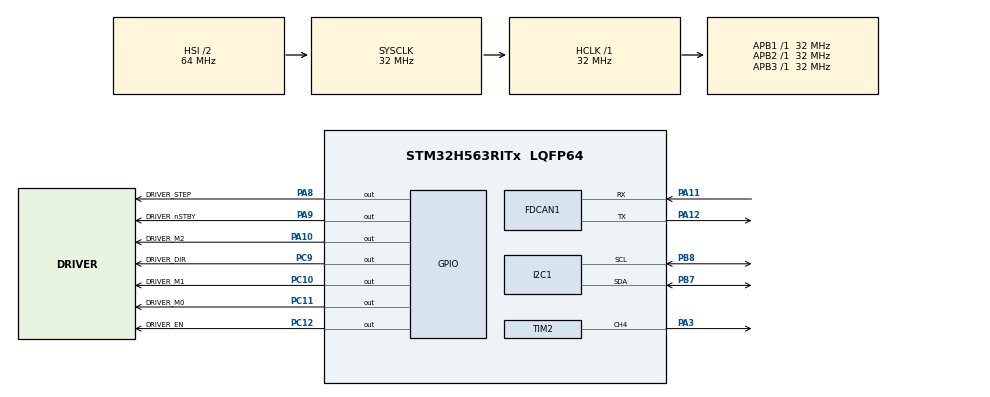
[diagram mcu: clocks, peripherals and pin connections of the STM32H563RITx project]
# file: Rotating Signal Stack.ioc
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BOOTPATH.BootPathName=LEGACY
BOOTPATH.UserSelectedBootPath=LEGACY
CORTEX_M33_NS.Number-Cortex_Memory_Protection_Unit_Region0_OTP_RO_AREAS_Settings=MPU_REGION_NUMBER0
CORTEX_M33_NS.default_mode_Activation=1
CORTEX_M33_NS.userName=CORTEX_M33
FDCAN1.CalculateBaudRateNominal=520833
FDCAN1.CalculateTimeBitNominal=1920
FDCAN1.CalculateTimeQuantumNominal=640.0
I2C1.Timing=0x00707CBB
Mcu.Family=STM32H5
Mcu.Name=STM32H563RITx
Mcu.Package=LQFP64
NVIC.PriorityGroup=NVIC_PRIORITYGROUP_4
NVIC.TIM2_IRQn=true\:0\:0\:false\:false\:true\:true\:true\:true
PA10.GPIO_Label=DRIVER_M2
PA10.Signal=GPIO_Output
PA11.Mode=FDCAN_Activate
PA11.Signal=FDCAN1_RX
PA12.Mode=FDCAN_Activate
PA12.Signal=FDCAN1_TX
PA13(JTMS/SWDIO).Mode=JTAG_4_pins
PA13(JTMS/SWDIO).Signal=DEBUG_JTMS-SWDIO
PA14(JTCK/SWCLK).Mode=JTAG_4_pins
PA14(JTCK/SWCLK).Signal=DEBUG_JTCK-SWCLK
PA15(JTDI).Mode=JTAG_4_pins
PA15(JTDI).Signal=DEBUG_JTDI
PA3.Signal=S_TIM2_CH4
PA8.GPIO_Label=DRIVER_STEP
PA8.Signal=GPIO_Output
PA9.GPIO_Label=DRIVER_nSTBY
PA9.Signal=GPIO_Output
PB3(JTDO/TRACESWO).Mode=JTAG_4_pins
PB3(JTDO/TRACESWO).Signal=DEBUG_JTDO-SWO
PB7.Mode=I2C
PB7.Signal=I2C1_SDA
PB8.Mode=I2C
PB8.Signal=I2C1_SCL
PC10.GPIO_Label=DRIVER_M1
PC10.Signal=GPIO_Output
PC11.GPIO_Label=DRIVER_M0
PC11.Signal=GPIO_Output
PC12.GPIO_Label=DRIVER_EN
PC12.Signal=GPIO_Output
PC9.GPIO_Label=DRIVER_DIR
PC9.Signal=GPIO_Output
ProjectManager.HeapSize=0x200
ProjectManager.StackSize=0x400
ProjectManager.TargetToolchain=STM32CubeIDE
RCC.ADCFreq_Value=32000000
RCC.AHBFreq_Value=32000000
RCC.APB1Freq_Value=32000000
RCC.APB1TimFreq_Value=32000000
RCC.APB2Freq_Value=32000000
RCC.APB2TimFreq_Value=32000000
RCC.APB3Freq_Value=32000000
RCC.CSI_VALUE=4000000
RCC.CortexFreq_Value=32000000
RCC.EPOD_VALUE=4000000
RCC.HCLKFreq_Value=32000000
RCC.HSE_VALUE=25000000
RCC.HSI48_VALUE=48000000
RCC.HSI_VALUE=64000000
RCC.LSE_VALUE=32768
RCC.LSIRC_VALUE=32000
RCC.SYSCLKFreq_VALUE=32000000
RCC.USBFreq_Value=48000000
RCC.VCOOutputFreq_Value=516000000
SH.S_TIM2_CH4.0=TIM2_CH4,PWM Generation4 CH4
TIM2.Channel-PWM\ Generation4\ CH4=TIM_CHANNEL_4
TIM2.PeriodNoDither=(32000000/20000) 
TIM2.Prescaler=20000
VP_BOOTPATH_VS_BOOTPATH.Mode=BP_Activate
VP_CORTEX_M33_NS_VS_Hclk.Mode=Hclk_Mode
VP_ICACHE_VS_ICACHE.Mode=DirectMappedCache
VP_MEMORYMAP_VS_MEMORYMAP.Mode=CurAppReg
VP_PWR_VS_LPOM.Mode=PowerOptimisation
VP_PWR_VS_SECSignals.Mode=Security/Privilege
VP_TIM2_VS_ClockSourceINT.Mode=Internal
board=custom

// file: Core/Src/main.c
/* USER CODE BEGIN Header */
/**
  ******************************************************************************
  * @file           : main.c
  * @brief          : Main program body
  ******************************************************************************
  * @attention
  *
  * Copyright (c) 2026 STMicroelectronics.
  * All rights reserved.
  *
  * This software is licensed under terms that can be found in the LICENSE file
  * in the root directory of this software component.
  * If no LICENSE file comes with this software, it is provided AS-IS.
  *
  ******************************************************************************
  */
/* USER CODE END Header */
#include "main.h"

/* USER CODE BEGIN PD */
#define TIM_DAY 1
/* USER CODE END PD */

FDCAN_HandleTypeDef hfdcan1;

I2C_HandleTypeDef hi2c1;

TIM_HandleTypeDef htim2;

void SystemClock_Config(void);
static void MPU_Config(void);
static void MX_GPIO_Init(void);
static void MX_ICACHE_Init(void);
static void MX_FDCAN1_Init(void);
static void MX_I2C1_Init(void);
static void MX_TIM2_Init(void);
/* USER CODE BEGIN PFP */
void HAL_TIM_PeriodElapsedCallback(TIM_HandleTypeDef *htim) {
    if (htim->Instance == TIM4) {
    	HAL_GPIO_TogglePin(HEARTBEAT_GPIO_Port, HEARTBEAT_Pin);
    }
}
/* USER CODE END PFP */

int main(void)
{

  /* MCU Configuration--------------------------------------------------------*/

  /* MPU Configuration--------------------------------------------------------*/
  MPU_Config();

  /* Reset of all peripherals, Initializes the Flash interface and the Systick. */
  HAL_Init();

  /* Configure the system clock */
  SystemClock_Config();

  /* Initialize all configured peripherals */
  MX_GPIO_Init();
  MX_ICACHE_Init();
  MX_FDCAN1_Init();
  MX_I2C1_Init();
  MX_TIM2_Init();
  /* USER CODE BEGIN 2 */
  HAL_TIM_Base_Start_IT(&htim2);
  __HAL_RCC_TIM2_CLK_ENABLE();
  HAL_GPIO_WritePin(DRIVER_M0_GPIO_Port, DRIVER_M0_Pin, GPIO_PIN_RESET);
  HAL_GPIO_WritePin(DRIVER_M1_GPIO_Port, DRIVER_M1_Pin, GPIO_PIN_RESET);
  HAL_GPIO_WritePin(DRIVER_M2_GPIO_Port, DRIVER_M2_Pin, GPIO_PIN_RESET);
  HAL_GPIO_WritePin(DRIVER_EN_GPIO_Port, DRIVER_EN_Pin, GPIO_PIN_RESET);
  HAL_GPIO_WritePin(DRIVER_DIRECTION_GPIO_Port, DRIVER_DIRECTION_Pin, GPIO_PIN_SET);
  HAL_GPIO_WritePin(DRIVER_STEP_CLOCK_GPIO_Port, DRIVER_STEP_CLOCK_Pin, GPIO_PIN_RESET);
  HAL_GPIO_WritePin(DRIVER_nSTBY_GPIO_Port, DRIVER_nSTBY_Pin, GPIO_PIN_SET);
  /* USER CODE END 2 */

  /* Infinite loop */
  /* USER CODE BEGIN WHILE */
  while (TIM_DAY)
  {
    /* USER CODE END WHILE */

  }
}

void SystemClock_Config(void)
{
  RCC_OscInitTypeDef RCC_OscInitStruct = {0};
  RCC_ClkInitTypeDef RCC_ClkInitStruct = {0};

  /** Configure the main internal regulator output voltage
  */
  __HAL_PWR_VOLTAGESCALING_CONFIG(PWR_REGULATOR_VOLTAGE_SCALE3);

  while(!__HAL_PWR_GET_FLAG(PWR_FLAG_VOSRDY)) {}

  /** Initializes the RCC Oscillators according to the specified parameters
  * in the RCC_OscInitTypeDef structure.
  */
  RCC_OscInitStruct.OscillatorType = RCC_OSCILLATORTYPE_HSI|RCC_OSCILLATORTYPE_HSE;
  RCC_OscInitStruct.HSEState = RCC_HSE_OFF;
  RCC_OscInitStruct.HSIState = RCC_HSI_ON;
  RCC_OscInitStruct.HSIDiv = RCC_HSI_DIV2;
  RCC_OscInitStruct.HSICalibrationValue = RCC_HSICALIBRATION_DEFAULT;
  RCC_OscInitStruct.PLL.PLLState = RCC_PLL_NONE;
  if (HAL_RCC_OscConfig(&RCC_OscInitStruct) != HAL_OK)
  {
    Error_Handler();
  }

  /** Initializes the CPU, AHB and APB buses clocks
  */
  RCC_ClkInitStruct.ClockType = RCC_CLOCKTYPE_HCLK|RCC_CLOCKTYPE_SYSCLK
                              |RCC_CLOCKTYPE_PCLK1|RCC_CLOCKTYPE_PCLK2
                              |RCC_CLOCKTYPE_PCLK3;
  RCC_ClkInitStruct.SYSCLKSource = RCC_SYSCLKSOURCE_HSI;
  RCC_ClkInitStruct.AHBCLKDivider = RCC_SYSCLK_DIV1;
  RCC_ClkInitStruct.APB1CLKDivider = RCC_HCLK_DIV1;
  RCC_ClkInitStruct.APB2CLKDivider = RCC_HCLK_DIV1;
  RCC_ClkInitStruct.APB3CLKDivider = RCC_HCLK_DIV1;

  if (HAL_RCC_ClockConfig(&RCC_ClkInitStruct, FLASH_LATENCY_1) != HAL_OK)
  {
    Error_Handler();
  }

  /** Configure the programming delay
  */
  __HAL_FLASH_SET_PROGRAM_DELAY(FLASH_PROGRAMMING_DELAY_0);
}

static void MX_FDCAN1_Init(void)
{

  hfdcan1.Instance = FDCAN1;
  hfdcan1.Init.ClockDivider = FDCAN_CLOCK_DIV1;
  hfdcan1.Init.FrameFormat = FDCAN_FRAME_CLASSIC;
  hfdcan1.Init.Mode = FDCAN_MODE_NORMAL;
  hfdcan1.Init.AutoRetransmission = DISABLE;
  hfdcan1.Init.TransmitPause = DISABLE;
  hfdcan1.Init.ProtocolException = DISABLE;
  hfdcan1.Init.NominalPrescaler = 16;
  hfdcan1.Init.NominalSyncJumpWidth = 1;
  hfdcan1.Init.NominalTimeSeg1 = 1;
  hfdcan1.Init.NominalTimeSeg2 = 1;
  hfdcan1.Init.DataPrescaler = 1;
  hfdcan1.Init.DataSyncJumpWidth = 1;
  hfdcan1.Init.DataTimeSeg1 = 1;
  hfdcan1.Init.DataTimeSeg2 = 1;
  hfdcan1.Init.StdFiltersNbr = 0;
  hfdcan1.Init.ExtFiltersNbr = 0;
  hfdcan1.Init.TxFifoQueueMode = FDCAN_TX_FIFO_OPERATION;
  if (HAL_FDCAN_Init(&hfdcan1) != HAL_OK)
  {
    Error_Handler();
  }

}

static void MX_I2C1_Init(void)
{

  hi2c1.Instance = I2C1;
  hi2c1.Init.Timing = 0x00707CBB;
  hi2c1.Init.OwnAddress1 = 0;
  hi2c1.Init.AddressingMode = I2C_ADDRESSINGMODE_7BIT;
  hi2c1.Init.DualAddressMode = I2C_DUALADDRESS_DISABLE;
  hi2c1.Init.OwnAddress2 = 0;
  hi2c1.Init.OwnAddress2Masks = I2C_OA2_NOMASK;
  hi2c1.Init.GeneralCallMode = I2C_GENERALCALL_DISABLE;
  hi2c1.Init.NoStretchMode = I2C_NOSTRETCH_DISABLE;
  if (HAL_I2C_Init(&hi2c1) != HAL_OK)
  {
    Error_Handler();
  }

  /** Configure Analogue filter
  */
  if (HAL_I2CEx_ConfigAnalogFilter(&hi2c1, I2C_ANALOGFILTER_ENABLE) != HAL_OK)
  {
    Error_Handler();
  }

  /** Configure Digital filter
  */
  if (HAL_I2CEx_ConfigDigitalFilter(&hi2c1, 0) != HAL_OK)
  {
    Error_Handler();
  }

}

static void MX_ICACHE_Init(void)
{

  /** Enable instruction cache in 1-way (direct mapped cache)
  */
  if (HAL_ICACHE_ConfigAssociativityMode(ICACHE_1WAY) != HAL_OK)
  {
    Error_Handler();
  }
  if (HAL_ICACHE_Enable() != HAL_OK)
  {
    Error_Handler();
  }

}

static void MX_TIM2_Init(void)
{

  TIM_ClockConfigTypeDef sClockSourceConfig = {0};
  TIM_MasterConfigTypeDef sMasterConfig = {0};
  TIM_OC_InitTypeDef sConfigOC = {0};

  htim2.Instance = TIM2;
  htim2.Init.Prescaler = 20000;
  htim2.Init.CounterMode = TIM_COUNTERMODE_UP;
  htim2.Init.Period = 1600;
  htim2.Init.ClockDivision = TIM_CLOCKDIVISION_DIV1;
  htim2.Init.AutoReloadPreload = TIM_AUTORELOAD_PRELOAD_DISABLE;
  if (HAL_TIM_Base_Init(&htim2) != HAL_OK)
  {
    Error_Handler();
  }
  sClockSourceConfig.ClockSource = TIM_CLOCKSOURCE_INTERNAL;
  if (HAL_TIM_ConfigClockSource(&htim2, &sClockSourceConfig) != HAL_OK)
  {
    Error_Handler();
  }
  if (HAL_TIM_PWM_Init(&htim2) != HAL_OK)
  {
    Error_Handler();
  }
  sMasterConfig.MasterOutputTrigger = TIM_TRGO_RESET;
  sMasterConfig.MasterSlaveMode = TIM_MASTERSLAVEMODE_DISABLE;
  if (HAL_TIMEx_MasterConfigSynchronization(&htim2, &sMasterConfig) != HAL_OK)
  {
    Error_Handler();
  }
  sConfigOC.OCMode = TIM_OCMODE_PWM1;
  sConfigOC.Pulse = 0;
  sConfigOC.OCPolarity = TIM_OCPOLARITY_HIGH;
  sConfigOC.OCFastMode = TIM_OCFAST_DISABLE;
  if (HAL_TIM_PWM_ConfigChannel(&htim2, &sConfigOC, TIM_CHANNEL_4) != HAL_OK)
  {
    Error_Handler();
  }
  HAL_TIM_MspPostInit(&htim2);

}

static void MX_GPIO_Init(void)
{
  GPIO_InitTypeDef GPIO_InitStruct = {0};

  /* GPIO Ports Clock Enable */
  __HAL_RCC_GPIOC_CLK_ENABLE();
  __HAL_RCC_GPIOH_CLK_ENABLE();
  __HAL_RCC_GPIOA_CLK_ENABLE();
  __HAL_RCC_GPIOB_CLK_ENABLE();

  /*Configure GPIO pin Output Level */
  HAL_GPIO_WritePin(GPIOC, DRIVER_EN_Pin|DRIVER_M0_Pin|DRIVER_M1_Pin, GPIO_PIN_RESET);

  /*Configure GPIO pin Output Level */
  HAL_GPIO_WritePin(GPIOH, DRIVER_M2_Pin|DRIVER_STEP_CLOCK_Pin, GPIO_PIN_RESET);

  /*Configure GPIO pin Output Level */
  HAL_GPIO_WritePin(HEARTBEAT_GPIO_Port, HEARTBEAT_Pin, GPIO_PIN_SET);

  /*Configure GPIO pin Output Level */
  HAL_GPIO_WritePin(DRIVER_nSTBY_GPIO_Port, DRIVER_nSTBY_Pin, GPIO_PIN_RESET);

  /*Configure GPIO pin Output Level */
  HAL_GPIO_WritePin(DRIVER_DIRECTION_GPIO_Port, DRIVER_DIRECTION_Pin, GPIO_PIN_RESET);

  /*Configure GPIO pins : DRIVER_EN_Pin DRIVER_M0_Pin DRIVER_M1_Pin HEARTBEAT_Pin */
  GPIO_InitStruct.Pin = DRIVER_EN_Pin|DRIVER_M0_Pin|DRIVER_M1_Pin|HEARTBEAT_Pin;
  GPIO_InitStruct.Mode = GPIO_MODE_OUTPUT_PP;
  GPIO_InitStruct.Pull = GPIO_NOPULL;
  GPIO_InitStruct.Speed = GPIO_SPEED_FREQ_LOW;
  HAL_GPIO_Init(GPIOC, &GPIO_InitStruct);

  /*Configure GPIO pins : DRIVER_M2_Pin DRIVER_STEP_CLOCK_Pin */
  GPIO_InitStruct.Pin = DRIVER_M2_Pin|DRIVER_STEP_CLOCK_Pin;
  GPIO_InitStruct.Mode = GPIO_MODE_OUTPUT_PP;
  GPIO_InitStruct.Pull = GPIO_NOPULL;
  GPIO_InitStruct.Speed = GPIO_SPEED_FREQ_LOW;
  HAL_GPIO_Init(GPIOH, &GPIO_InitStruct);

  /*Configure GPIO pin : DRIVER_nSTBY_Pin */
  GPIO_InitStruct.Pin = DRIVER_nSTBY_Pin;
  GPIO_InitStruct.Mode = GPIO_MODE_OUTPUT_PP;
  GPIO_InitStruct.Pull = GPIO_NOPULL;
  GPIO_InitStruct.Speed = GPIO_SPEED_FREQ_LOW;
  HAL_GPIO_Init(DRIVER_nSTBY_GPIO_Port, &GPIO_InitStruct);

  /*Configure GPIO pin : PA8 */
  GPIO_InitStruct.Pin = GPIO_PIN_8;
  GPIO_InitStruct.Mode = GPIO_MODE_INPUT;
  GPIO_InitStruct.Pull = GPIO_NOPULL;
  HAL_GPIO_Init(GPIOA, &GPIO_InitStruct);

  /*Configure GPIO pin : DRIVER_DIRECTION_Pin */
  GPIO_InitStruct.Pin = DRIVER_DIRECTION_Pin;
  GPIO_InitStruct.Mode = GPIO_MODE_OUTPUT_PP;
  GPIO_InitStruct.Pull = GPIO_NOPULL;
  GPIO_InitStruct.Speed = GPIO_SPEED_FREQ_LOW;
  HAL_GPIO_Init(DRIVER_DIRECTION_GPIO_Port, &GPIO_InitStruct);

}

 /* MPU Configuration */

void MPU_Config(void)
{
  MPU_Region_InitTypeDef MPU_InitStruct = {0};
  MPU_Attributes_InitTypeDef MPU_AttributesInit = {0};

  /* Disables the MPU */
  HAL_MPU_Disable();

  /** Initializes and configures the Region 0 and the memory to be protected
  */
  MPU_InitStruct.Enable = MPU_REGION_ENABLE;
  MPU_InitStruct.Number = MPU_REGION_NUMBER0;
  MPU_InitStruct.BaseAddress = 0x08FFF000;
  MPU_InitStruct.LimitAddress = 0x08FFFFFF;
  MPU_InitStruct.AttributesIndex = MPU_ATTRIBUTES_NUMBER0;
  MPU_InitStruct.AccessPermission = MPU_REGION_ALL_RO;
  MPU_InitStruct.DisableExec = MPU_INSTRUCTION_ACCESS_DISABLE;
  MPU_InitStruct.IsShareable = MPU_ACCESS_NOT_SHAREABLE;

  HAL_MPU_ConfigRegion(&MPU_InitStruct);

  /** Initializes and configures the Attribute 0 and the memory to be protected
  */
  MPU_AttributesInit.Number = MPU_ATTRIBUTES_NUMBER0;
  MPU_AttributesInit.Attributes = INNER_OUTER(MPU_NOT_CACHEABLE);

  HAL_MPU_ConfigMemoryAttributes(&MPU_AttributesInit);
  /* Enables the MPU */
  HAL_MPU_Enable(MPU_PRIVILEGED_DEFAULT);

}

void Error_Handler(void)
{
  __disable_irq();
  while (1)
  {
  }
}
